# ADuCM322i register map
Vendor: Analog Devices Inc.; Series: ARMCM3; File version: 1.0
CPU: CM3 r2p1, little endian, no MPU, no FPU, 3 interrupt priority bits
Registers are 16-bit, read-write, no defined reset value unless marked. A register's access mark holds for its fields unless they carry their own. Offsets are from the block's base; [hi:lo] are bit positions.

## SPI0 — Serial Peripheral Interface 0
Base 0x4002C000
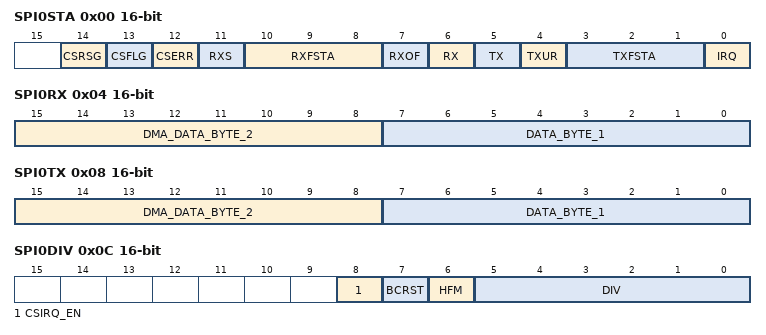
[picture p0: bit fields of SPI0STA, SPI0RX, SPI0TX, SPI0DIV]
0x00 SPI0STA ro read-modifies — Status register
  [14] CSRSG — Detected a rising edge on CS, in CONT mode
    0=CLR (Cleared to 0 when the Status register is read.); 1=SET (Set to 1 when there was a rising edge in CS line, when the device was in master mode, continuous transfer, High Frequency mode and CSIRQ_EN was asserted.)
  [13] CSFLG — Detected a falling edge on CS, in CONT mode
    0=CLR (Cleared to 0 when the Status register is read.); 1=SET (Set to 1 when there was a falling edge in CS line, when the device was in master mode, continuous transfer, High Frequency mode and CSIRQ_EN was asserted)
  [12] CSERR — Detected a CS error condition
    0=CLR (Cleared to 0 when the Status register is read.); 1=SET (Set to 1 when the CS line was de-asserted abruptly, even before the full-byte of data was transmitted completely. This bit will cause an interrupt.)
  [11] RXS — SPI Rx FIFO excess bytes present
    0=CLR (This bit is cleared when the number of bytes in the FIFO is equal or less than the number in SPI0CON[15:14].); 1=SET (This bit is set when there are more bytes in the Rx FIFO than indicated in the MOD bits in SPI0CON.)
  [10:8] RXFSTA — SPI Rx FIFO status
    0=EMPTY (Rx FIFO empty); 1=ONEBYTE (1 valid byte in FIFO); 2=TWOBYTES (2 valid bytes in the FIFO); 3=THREEBYTES (3 valid bytes in the FIFO); 4=FOURBYTES (4 valid bytes in the FIFO)
  [7] RXOF — SPI Rx FIFO overflow
    0=CLR (Cleared when the SPISTA register is read.); 1=SET (Set when the Rx FIFO was already full when new data was loaded to the FIFO. This bit generates an interrupt except when RFLUSH is set in SPI0CON.)
  [6] RX — SPI Rx IRQ
    0=CLR (Cleared when the SPI0STA register is read.); 1=SET (Set when a receive interrupt occurs. This bit is set when TIM in SPI0CON is cleared and the required number of bytes have been received.)
  [5] TX — SPI Tx IRQ
    0=CLR (Cleared to 0 when the SPI0STA register is read.); 1=SET (Set to 1 when a transmit interrupt occurs. This bit is set when TIM in SPI0CON is set and the required number of bytes have been transmitted.)
  [4] TXUR — SPI Tx FIFO underflow
    0=CLR (Cleared to 0 when the SPI0STA register is read.); 1=SET (Set to 1 when a transmit is initiated without any valid data in the Tx FIFO. This bit generates an interrupt except when TFLUSH is set in SPI0CON.)
  [3:1] TXFSTA — SPI Tx FIFO status
    0=EMPTY (Tx FIFO empty); 1=ONEBYTE (1 valid byte in FIFO); 2=TWOBYTES (2 valid bytes in FIFO); 3=THREEBYTES (3 valid bytes in FIFO); 4=FOURBYTES (4 valid bytes in FIFO)
  [0] IRQ — SPI Interrupt status
    0=CLR (Cleared to 0 after reading SPI0STA.); 1=SET (Set to 1 when an SPI based interrupt occurs.)
0x04 SPI0RX ro read-modifies — Receive register
  [15:8] DMA_DATA_BYTE_2 range 0x00000000..0x000000FF — 8-bit receive buffer
  [7:0] DATA_BYTE_1 range 0x00000000..0x000000FF — 8-bit receive buffer
0x08 SPI0TX wo — Transmit register
  [15:8] DMA_DATA_BYTE_2 range 0x00000000..0x000000FF — 8-bit transmit buffer
  [7:0] DATA_BYTE_1 range 0x00000000..0x000000FF — 8-bit transmit buffer
0x0C SPI0DIV — Baud rate selection register
  [8] CSIRQ_EN range 0x00000000..0x00000001 — Enable interrupt on every CS edge in CONT mode
  [7] BCRST range 0x00000000..0x00000001 — Reset Mode for CSERR
  [6] HFM range 0x00000000..0x00000001 — High Frequency Mode
  [5:0] DIV range 0x00000000..0x0000003F — SPI clock divider
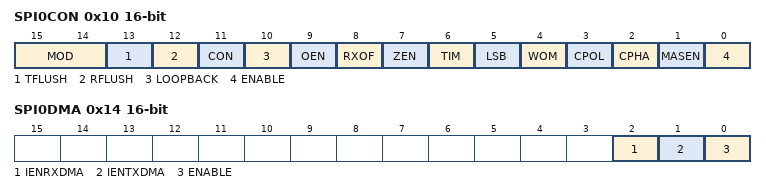
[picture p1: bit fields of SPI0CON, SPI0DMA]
0x10 SPI0CON — SPI configuration register
  [15:14] MOD — SPI IRQ mode bits
    0=TX1RX1 (Tx interrupt occurs when 1 byte has been transferred. Rx interrupt occurs when 1 or more bytes have been received into the FIFO.); 1=TX2RX2 (Tx interrupt occurs when 2 bytes has been transferred. Rx interrupt occurs when 2 or more bytes have been received into the FIFO.); 2=TX3RX3 (Tx interrupt occurs when 3 bytes has been transferred. Rx interrupt occurs when 3 or more bytes have been received into the FIFO.); 3=TX4RX4 (Tx interrupt occurs when 4 bytes has been transferred. Rx interrupt occurs when the Rx FIFO is full, or 4 bytes present.)
  [13] TFLUSH — SPI Tx FIFO Flush enable
    0=DIS (Clear this bit to disable Tx FIFO flushing.); 1=EN (Set this bit to flush the Tx FIFO. This bit does not clear itself and should be toggled if a single flush is required. If this bit is left high, then either the last transmitted value or "0x00" is transmitted depending on the ZEN bit. Any writes to the Tx FIFO are ignored while this bit is set.)
  [12] RFLUSH — SPI Rx FIFO Flush enable
    0=DIS (Clear this bit to disable Rx FIFO flushing.); 1=EN (Set this bit to flush the Rx FIFO. This bit does not clear itself and should be toggled if a single flush is required. If this bit is set all incoming data is ignored and no interrupts are generated. If set and TIM = 0, a read of the Rx FIFO will initiate a transfer.)
  [11] CON — Continuous transfer enable
    0=DIS (Cleared by user to disable continuous transfer. Each transfer consists of a single 8-bit serial transfer. If valid data exists in the SPI0TX register, then a new transfer is initiated after a stall period of 1 serial clock cycle.); 1=EN (Set by user to enable continuous transfer. In master mode, the transfer continues until no valid data is available in the Tx register. CS is asserted and remains asserted for the duration of each 8-bit serial transfer until Tx is empty.)
  [10] LOOPBACK — Loopback enable
    0=DIS (Cleared by user to be in normal mode.); 1=EN (Set by user to connect MISO to MOSI and test software.)
  [9] OEN — Slave MISO output enable
    0=DIS (Clear this bit to disable the output driver on the MISO pin. The MISO pin will be Open-Circuit when this bit is clear.); 1=EN (Set this bit for MISO to operate as normal.)
  [8] RXOF — SPIRX overflow overwrite enable
    0=DIS (Cleared by user, the new serial byte received is discarded.); 1=EN (Set by user, the valid data in the Rx register is overwritten by the new serial byte received.)
  [7] ZEN — Transmit zeros enable
    0=DIS (Clear this bit to transmit the last transmitted value when there is no valid data in the Tx FIFO.); 1=EN (Set this bit to transmit "0x00" when there is no valid data in the Tx FIFO.)
  [6] TIM — SPI transfer and interrupt mode
    0=RXRD (Cleared by user to initiate transfer with a read of the SPI0RX register. Interrupt only occurs when Rx is full.); 1=TXWR (Set by user to initiate transfer with a write to the SPI0TX register. Interrupt only occurs when Tx is empty.)
  [5] LSB — LSB first transfer enable
    0=DIS (MSB transmitted first); 1=EN (LSB transmitted first)
  [4] WOM — SPI Wired Or mode
    1=EN (Enables open circuit data output enable. External pull-ups required on data out pins); 0=DIS (Normal output levels)
  [3] CPOL — Serial Clock Polarity
    0=LOW (Serial clock idles low); 1=HIGH (Serial clock idles high)
  [2] CPHA — Serial clock phase mode
    1=SAMPLETRAILING (Serial clock pulses at the beginning of each serial bit transfer); 0=SAMPLELEADING (Serial clock pulses at the end of each serial bit transfer)
  [1] MASEN — Master mode enable
    0=DIS (Enable slave mode); 1=EN (Enable master mode)
  [0] ENABLE — SPI enable
    0=DIS (Disable the SPI); 1=EN (Enable the SPI)
0x14 SPI0DMA — SPI DMA enable register
  [2] IENRXDMA — Enable receive DMA request
    0=DIS (Disable RX DMA Interrupt); 1=EN (Enable RX DMA Interrupt)
  [1] IENTXDMA — Enable transmit DMA request
    0=DIS (Disable TX DMA Interrupt); 1=EN (Enable TX DMA Interrupt)
  [0] ENABLE range 0x00000000..0x00000001 — Enable DMA for data transfer
0x18 SPI0CNT — Transfer byte count register
  [7:0] COUNT range 0x00000000..0x000000FF — Transfer byte count
